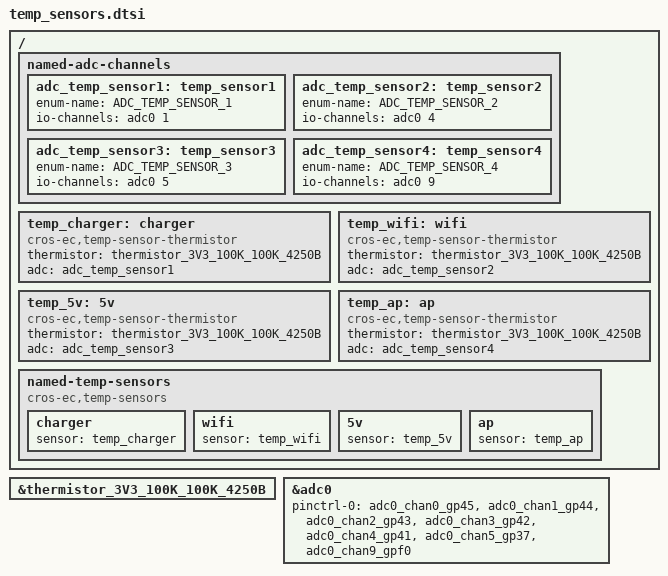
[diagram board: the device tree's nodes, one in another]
/* Copyright 2025 The ChromiumOS Authors
 * Use of this source code is governed by a BSD-style license that can be
 * found in the LICENSE file.
 */
#include <cros/thermistor/thermistor.dtsi>

/ {
	named-adc-channels {

		adc_temp_sensor1: temp_sensor1 {
			enum-name = "ADC_TEMP_SENSOR_1";
			io-channels = <&adc0 1>;
		};
		adc_temp_sensor2: temp_sensor2 {
			enum-name = "ADC_TEMP_SENSOR_2";
			io-channels = <&adc0 4>;
		};
		adc_temp_sensor3: temp_sensor3 {
			enum-name = "ADC_TEMP_SENSOR_3";
			io-channels = <&adc0 5>;
		};
		adc_temp_sensor4: temp_sensor4 {
			enum-name = "ADC_TEMP_SENSOR_4";
			io-channels = <&adc0 9>;
		};
	};

	temp_charger: charger {
		compatible = "cros-ec,temp-sensor-thermistor";
		thermistor = <&thermistor_3V3_100K_100K_4250B>;
		adc = <&adc_temp_sensor1>;
	};
	temp_wifi: wifi {
		compatible = "cros-ec,temp-sensor-thermistor";
		thermistor = <&thermistor_3V3_100K_100K_4250B>;
		adc = <&adc_temp_sensor2>;
	};
	temp_5v: 5v {
		compatible = "cros-ec,temp-sensor-thermistor";
		thermistor = <&thermistor_3V3_100K_100K_4250B>;
		adc = <&adc_temp_sensor3>;
	};
	temp_ap: ap {
		compatible = "cros-ec,temp-sensor-thermistor";
		thermistor = <&thermistor_3V3_100K_100K_4250B>;
		adc = <&adc_temp_sensor4>;
	};

	named-temp-sensors {
		compatible = "cros-ec,temp-sensors";
		charger {
			sensor = <&temp_charger>;
		};
		wifi {
			sensor = <&temp_wifi>;
		};
		5v {
			sensor = <&temp_5v>;
		};
		ap {
			sensor = <&temp_ap>;
		};
	};
};

&thermistor_3V3_100K_100K_4250B {
	status = "okay";
};

&adc0 {
	pinctrl-0 = <&adc0_chan0_gp45
		&adc0_chan1_gp44
		&adc0_chan2_gp43
		&adc0_chan3_gp42
		&adc0_chan4_gp41
		&adc0_chan5_gp37
		&adc0_chan9_gpf0>;
	pinctrl-names = "default";
};
